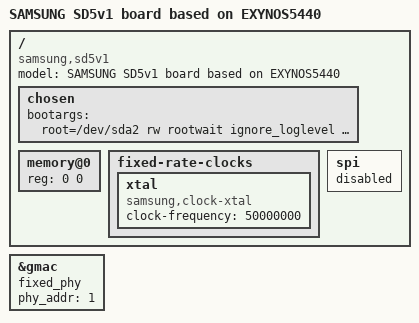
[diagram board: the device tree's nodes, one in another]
// SPDX-License-Identifier: GPL-2.0
/*
 * SAMSUNG SD5v1 board device tree source
 *
 * Copyright (c) 2013 Samsung Electronics Co., Ltd.
 *		http://www.samsung.com
 */

/dts-v1/;
#include "exynos5440.dtsi"

/ {
	model = "SAMSUNG SD5v1 board based on EXYNOS5440";
	compatible = "samsung,sd5v1", "samsung,exynos5440", "samsung,exynos5";

	chosen {
		bootargs = "root=/dev/sda2 rw rootwait ignore_loglevel earlyprintk no_console_suspend mem=2048M@0x80000000 mem=6144M@0x100000000 console=ttySAC0,115200";
	};

	/* FIXME: set reg property with correct start address and size */
	memory@0 {
		device_type = "memory";
		reg = <0 0>;
	};

	fixed-rate-clocks {
		xtal {
			compatible = "samsung,clock-xtal";
			clock-frequency = <50000000>;
		};
	};

	spi {
		status = "disabled";
	};

};

&gmac {
	fixed_phy;
	phy_addr = <1>;
};
